# WE2_S_NS register map
Vendor: ARM Ltd.; Series: ARMv8.1-M Mainline; File version: 1.0
CPU: CM55 r1p1, little endian, MPU, FPU, double-precision FPU, DSP, VTOR, 3 interrupt priority bits
Registers are 32-bit, read-write, reset 0x0 unless marked. A register's access mark holds for its fields unless they carry their own. Offsets are from the block's base; [hi:lo] are bit positions.

## SYS_SCB — System control block
Base 0xE000ED00
Same registers: SYS_SCB_NS 0xE002ED00
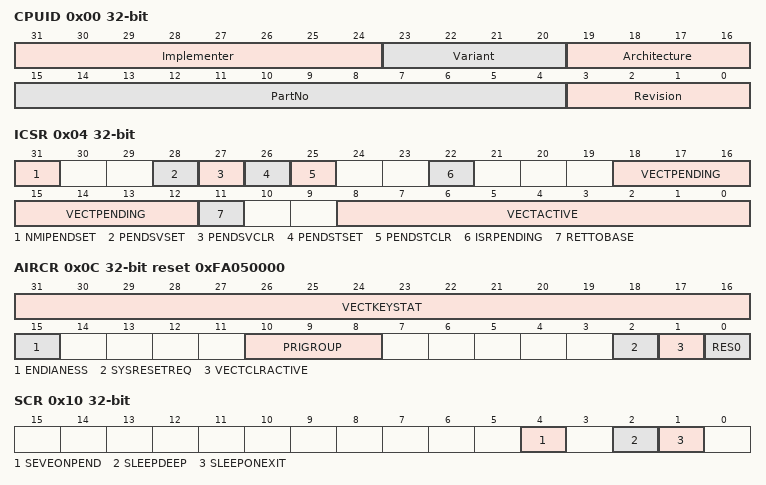
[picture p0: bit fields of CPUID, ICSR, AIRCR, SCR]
0x00 CPUID ro — CPUID base register
  [31:24] Implementer — Implementer code
  [23:20] Variant — Variant number
  [19:16] Architecture — Reads as 0b1111, Armv8.1-M with Main Extension
  [15:4] PartNo — Part number of the processor
  [3:0] Revision — Revision number
0x04 ICSR — Interrupt control and state register
  [31] NMIPENDSET — NMI set-pending bit.
  [28] PENDSVSET — PendSV set-pending bit
  [27] PENDSVCLR — PendSV clear-pending bit
  [26] PENDSTSET — SysTick exception set-pending bit
  [25] PENDSTCLR — SysTick exception clear-pending bit
  [22] ISRPENDING — Interrupt pending flag
  [18:12] VECTPENDING — Pending vector
  [11] RETTOBASE — Return to base level
  [8:0] VECTACTIVE — Active vector
0x08 VTOR — Vector table offset register
  [29:9] TBLOFF — Vector table base offset field
0x0C AIRCR reset 0xFA050000 (reset mask 0xFFFF0FFF) — Application interrupt and reset control register
  [31:16] VECTKEYSTAT — Write 0x5FA to VECTKEY, otherwise the write is ignored.
  [15] ENDIANESS
  [10:8] PRIGROUP
  [2] SYSRESETREQ
  [1] VECTCLRACTIVE wo
  [0] RES0 — Reserved_
0x10 SCR — System control register
  [4] SEVEONPEND — Send Event on Pending bit
  [2] SLEEPDEEP
  [1] SLEEPONEXIT
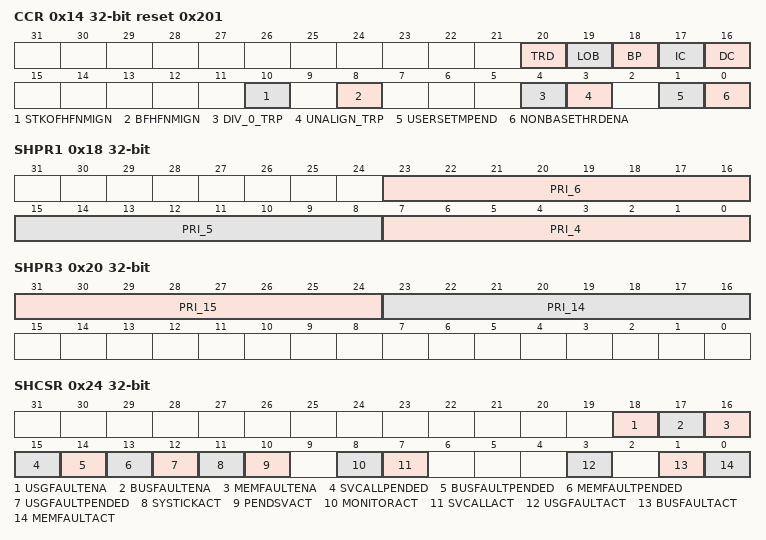
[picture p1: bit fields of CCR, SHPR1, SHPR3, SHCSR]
0x14 CCR reset 0x201 — Configuration and control register
  [20] TRD — Thread reentrancy disabled
  [19] LOB — Loop and branch info cache enable
  [18] BP — Branch prediction enable
  [17] IC — Instruction cache enable
  [16] DC — Data cache enable
  [10] STKOFHFNMIGN
  [8] BFHFNMIGN
  [4] DIV_0_TRP
  [3] UNALIGN_TRP
  [1] USERSETMPEND
  [0] NONBASETHRDENA — Configures how the processor enters Thread mode
0x18 SHPR1 — System handler priority registers
  [23:16] PRI_6 — Priority of system handler 6
  [15:8] PRI_5 — Priority of system handler 5
  [7:0] PRI_4 — Priority of system handler 4
0x1C SHPR2 — System handler priority registers
  [31:24] PRI_11 — Priority of system handler 11
0x20 SHPR3 — System handler priority registers
  [31:24] PRI_15 — Priority of system handler 15
  [23:16] PRI_14 — Priority of system handler 14
0x24 SHCSR — System handler control and state register
  [18] USGFAULTENA — Usage fault enable bit
  [17] BUSFAULTENA — Bus fault enable bit
  [16] MEMFAULTENA — Memory management fault enable bit
  [15] SVCALLPENDED — SVC call pending bit
  [14] BUSFAULTPENDED — Bus fault exception pending bit
  [13] MEMFAULTPENDED — Memory management fault exception pending bit
  [12] USGFAULTPENDED — Usage fault exception pending bit
  [11] SYSTICKACT — SysTick exception active bit
  [10] PENDSVACT — PendSV exception active bit
  [8] MONITORACT — Debug monitor active bit
  [7] SVCALLACT — SVC call active bit
  [3] USGFAULTACT — Usage fault exception active bit
  [1] BUSFAULTACT — Bus fault exception active bit
  [0] MEMFAULTACT — Memory management fault exception active bit
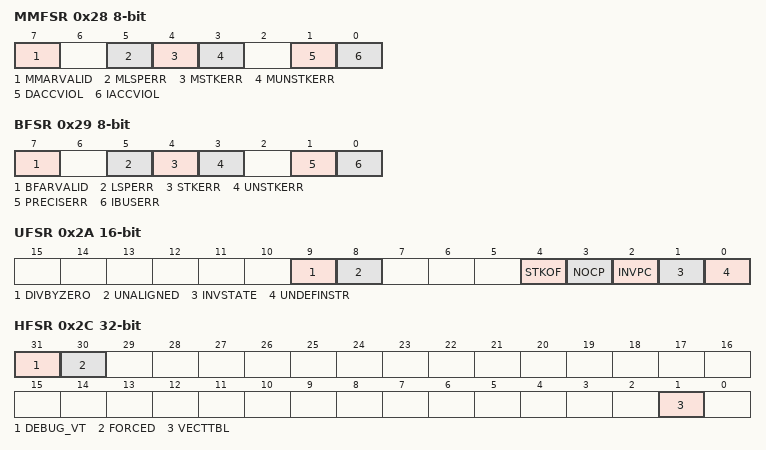
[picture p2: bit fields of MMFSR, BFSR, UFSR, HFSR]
0x28 MMFSR 8-bit — MemManage Fault Status Register
  [7] MMARVALID, [5] MLSPERR, [4] MSTKERR, [3] MUNSTKERR, [1] DACCVIOL, [0] IACCVIOL
0x29 BFSR 8-bit — BusFault Status Register
  [7] BFARVALID — BusFault Address Register (BFAR) valid flag
  [5] LSPERR
  [4] STKERR — BusFault on stacking for exception entry
  [3] UNSTKERR — BusFault on unstacking for a return from exception
  [1] PRECISERR — Precise data bus error
  [0] IBUSERR — Instruction bus error
0x2A UFSR 16-bit — UsageFault Status Register
  [9] DIVBYZERO, [8] UNALIGNED, [4] STKOF, [3] NOCP, [2] INVPC, [1] INVSTATE, [0] UNDEFINSTR
0x2C HFSR — Hard fault status register
  [31] DEBUG_VT — Reserved for Debug use
  [30] FORCED — Forced hard fault
  [1] VECTTBL — Vector table hard fault
0x30 DFSR — Debug Fault Status Register
0x34 MMFAR — Memory management fault address register
0x38 BFAR — Bus fault address register
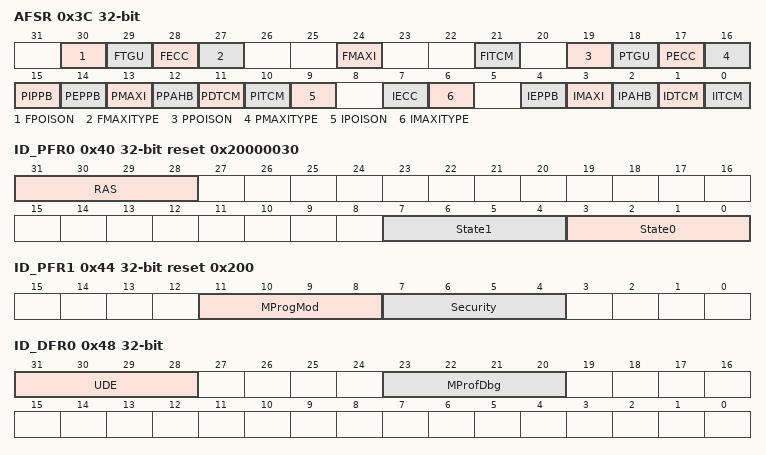
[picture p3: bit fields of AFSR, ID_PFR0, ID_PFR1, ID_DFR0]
0x3C AFSR ro — Auxiliary fault status register
  [30] FPOISON — Fetch fault that is caused by RPOISON or TEBRx.POISON
  [29] FTGU — Fetch fault that is caused by TCM Gate Unit (TGU) security violation
  [28] FECC — Fetch fault that is caused by uncorrectable Error Correcting Code (ECC) error
  [27] FMAXITYPE — AXI response that caused the fetch fault. Only valid when AFSR.FMAXI is 1
  [24] FMAXI — Fetch fault on Manager AXI (M-AXI) interface
  [21] FITCM — Fetch fault on Instruction Tightly Coupled Memory (ITCM) interface
  [19] PPOISON — Precise fault that is caused by RPOISON or TEBRx.POISON
  [18] PTGU — Precise fault that is caused by TGU security violation
  [17] PECC — Precise fault that is caused by uncorrectable ECC error
  [16] PMAXITYPE — AXI response that caused the precise fault. Only valid when AFSR.PMAXI is 1
  [15] PIPPB — Precise fault on Internal Private Peripheral Bus (IPPB) interface
  [14] PEPPB — Precise fault on External Private Peripheral Bus (EPPB) interfacee
  [13] PMAXI — Precise fault on M-AXI interface
  [12] PPAHB — Precise fault on P-PAHB interface
  [11] PDTCM — Precise fault on DTCM interface
  [10] PITCM — Precise fault on ITCM interface
  [9] IPOISON — Imprecise BusFault because of RPOISON
  [7] IECC — Imprecise fault that is caused by uncorrectable ECC error
  [6] IMAXITYPE — AXI response that caused the imprecise fault. Only valid when AFSR.IMAXI is 1
  [4] IEPPB — Imprecise fault on EPPB interface
  [3] IMAXI — Imprecise fault on M-AXI interface
  [2] IPAHB — Imprecise fault on P-AHB interface
  [1] IDTCM — Imprecise fault on DTCM interface
  [0] IITCM — Imprecise fault on ITCM interface
0x40 ID_PFR0 ro reset 0x20000030 — Processor Feature Register 0
  [31:28] RAS — Identifies which version of the RAS architecture is implemented
  [7:4] State1 — T32 instruction set support
  [3:0] State0 — A32 instruction set support
0x44 ID_PFR1 ro reset 0x200 (reset mask 0xFFFFFF0F) — Processor Feature Register 1
  [11:8] MProgMod — 0b0010 is M-profile programmers model. Identifies support for the M-profile programmers model
  [7:4] Security — 0b0000 is Security. Identifies whether the Security Extension in implemented
0x48 ID_DFR0 ro — Debug Feature Register 0
  [31:28] UDE, [23:20] MProfDbg
0x4C ID_AFR0 ro — Auxiliary Feature Register 0
0x50 ID_MMFR0 ro reset 0x111040 — Memory Model Feature Register 0
0x54 ID_MMFR1 ro — Memory Model Feature Register 1
0x58 ID_MMFR2 ro reset 0x1000000 — Memory Model Feature Register 2
0x5C ID_MMFR3 ro reset 0x11 — Memory Model Feature Register 3
0x60 ID_ISAR0 ro reset 0x1103110 — Instruction Set Attribute Register 0
0x64 ID_ISAR1 ro reset 0x2212000 — Instruction Set Attribute Register 1
0x68 ID_ISAR2 ro reset 0x20232232 — Instruction Set Attribute Register 2
0x6C ID_ISAR3 ro reset 0x1111131 — Instruction Set Attribute Register 3
0x70 ID_ISAR4 ro reset 0x1310132 — Instruction Set Attribute Register 4
0x74 ID_ISAR5 ro — Instruction Set Attribute Register 5
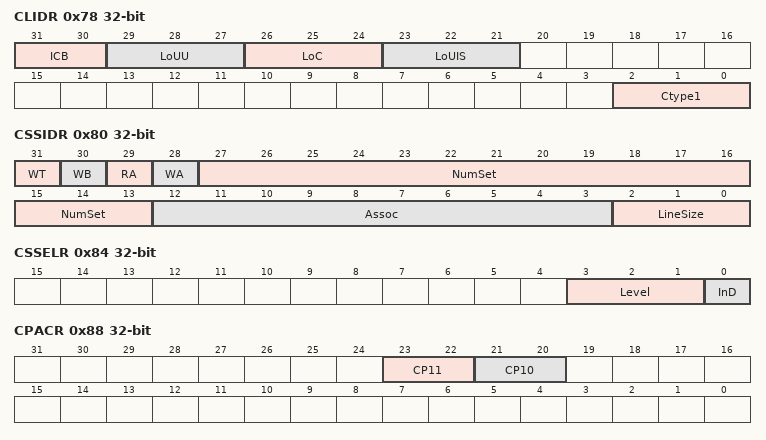
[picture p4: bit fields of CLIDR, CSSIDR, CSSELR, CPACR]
0x78 CLIDR ro — Cache Level ID Register
  [31:30] ICB — Inner cache boundary: [0b00] Not disclosed in this mechanism
  [29:27] LoUU — Level of Unification Uniprocessor: [0b000] Caches are not implemented. [0b001] Level 1 (L1) data cache or instruction cache is implemented.
  [26:24] LoC — Level of Coherency: [0b000] Caches are not implemented. [0b001] L1 data cache or instruction cache is implemented.
  [23:21] LoUIS — Level of Unification Inner Shareable: [0b000] Caches are not implemented. [0b001] L1 data cache or instruction cache is implemented.
  [2:0] Ctype1 — Level 1 (L1) cache type: [0b000] Caches are not implemented. [0b001] Only instruction cache is implemented. [0b010] Only data cache is implemented. [0b011] Both data cache and instruction cache are implemented
0x7C CTR ro — Cache Type Register
0x80 CSSIDR ro — Current Cache Size ID Register
  [31] WT — Indicates support available for Write-Through: [0b1] Write-Through support available
  [30] WB — Indicates support available for Write-Back: [0b1] Write-Back support available
  [29] RA — Indicates support available for read allocation: [0b1] Read allocation support available
  [28] WA — Indicates support available for write allocation: [0b1] Write allocation support available.
  [27:13] NumSet — Indicates the number of sets. Cache-size dependent.
  [12:3] Assoc — Indicates associativity: When CSSELR.InD=1 (L1 instruction cache): [0x1] 2-way set associative instruction cache. When CSSELR.InD=0 (L1 data cache): [0x3] 4-way set associative data cache
  [2:0] LineSize — Indicates the number of words in each cache line. 0b1 Represents 32 bytes
0x84 CSSELR — Cache Size Selection Register
  [3:1] Level ro — Identifies which cache level to select: [0] L1 data cache. [1] L1 instruction cache.
  [0] InD — Selects either L1 instruction or data cache: [0x0] L1 cache
0x88 CPACR — Coprocessor access control register
  [23:22] CP11, [21:20] CP10
0x8C NSACR — Non-secure Access Control Register
